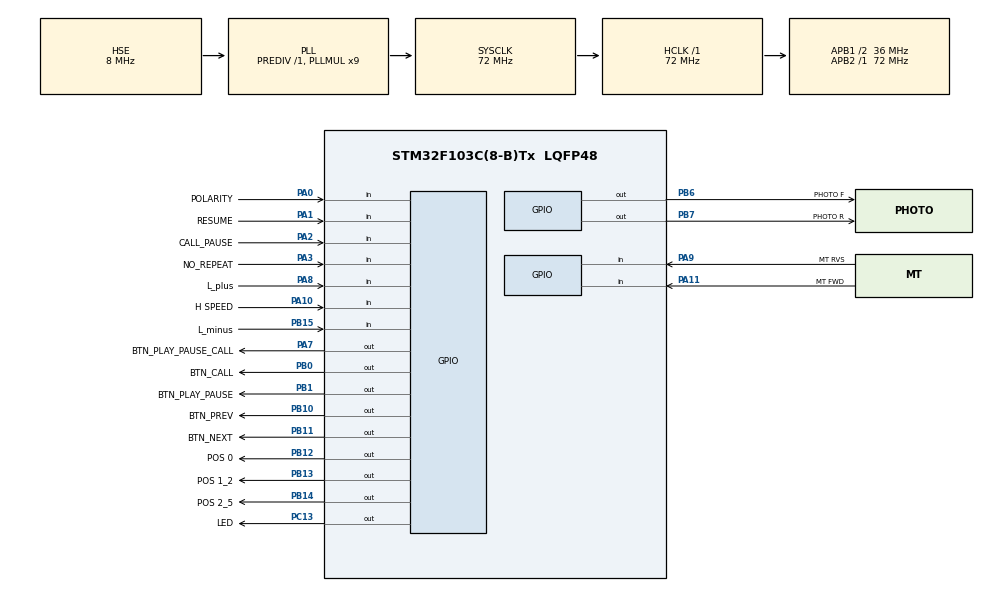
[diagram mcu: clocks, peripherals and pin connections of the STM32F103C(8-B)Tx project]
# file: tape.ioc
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Mcu.Family=STM32F1
PA2.GPIO_PuPd=GPIO_PULLUP
PB14.GPIO_Label=POS 2_5
PA3.GPIO_PuPd=GPIO_PULLUP
PA7.GPIO_ModeDefaultOutputPP=GPIO_MODE_OUTPUT_OD
PB0.GPIO_Label=BTN_CALL
PB6.GPIO_Label=PHOTO F
PB13.GPIO_Label=POS 1_2
PB11.Signal=GPIO_Output
PB13.Signal=GPIO_Output
PB15.Signal=GPIO_Input
RCC.SYSCLKSource=RCC_SYSCLKSOURCE_PLLCLK
ProjectManager.StackSize=0x10
PD1-OSC_OUT.Signal=RCC_OSC_OUT
PB10.GPIO_ModeDefaultOutputPP=GPIO_MODE_OUTPUT_OD
RCC.HCLKFreq_Value=72000000
RCC.APB2TimFreq_Value=72000000
PB6.Signal=GPIO_Output
PB13.GPIO_ModeDefaultOutputPP=GPIO_MODE_OUTPUT_OD
PB12.PinState=GPIO_PIN_SET
PA1.GPIO_PuPd=GPIO_PULLUP
RCC.AHBFreq_Value=72000000
PB12.GPIO_ModeDefaultOutputPP=GPIO_MODE_OUTPUT_OD
RCC.PLLMUL=RCC_PLL_MUL9
PB12.GPIO_Label=POS 0
PA14.Mode=Serial_Wire
PB1.GPIO_Label=BTN_PLAY_PAUSE
PA10.GPIO_Label=H SPEED
PB7.Signal=GPIO_Output
PA8.Signal=GPIO_Input
PB7.GPIO_Label=PHOTO R
Mcu.Package=LQFP48
PB1.Signal=GPIO_Output
PA2.GPIO_Label=CALL_PAUSE
PB6.GPIO_ModeDefaultOutputPP=GPIO_MODE_OUTPUT_OD
PA10.Signal=GPIO_Input
RCC.APB1TimFreq_Value=72000000
PB0.GPIO_ModeDefaultOutputPP=GPIO_MODE_OUTPUT_OD
PA3.Signal=GPIO_Input
RCC.PLLSourceVirtual=RCC_PLLSOURCE_HSE
PD1-OSC_OUT.Mode=HSE-External-Oscillator
PA9.GPIO_Label=MT RVS
PB11.GPIO_Label=BTN_NEXT
PC13-TAMPER-RTC.Signal=GPIO_Output
PA11.GPIO_Label=MT FWD
PD0-OSC_IN.Signal=RCC_OSC_IN
RCC.APB1CLKDivider=RCC_HCLK_DIV2
PA0-WKUP.GPIO_Label=POLARITY
PA0-WKUP.Signal=GPIO_Input
PA13.Signal=SYS_JTMS-SWDIO
PA8.GPIO_Label=L_plus
PB14.PinState=GPIO_PIN_SET
ProjectManager.TargetToolchain=STM32CubeIDE
PB10.GPIO_Label=BTN_PREV
PA9.Signal=GPIO_Input
RCC.USBFreq_Value=72000000
PB14.GPIO_ModeDefaultOutputPP=GPIO_MODE_OUTPUT_OD
PB11.GPIO_ModeDefaultOutputPP=GPIO_MODE_OUTPUT_OD
PA1.Signal=GPIO_Input
PD0-OSC_IN.Mode=HSE-External-Oscillator
PB10.Signal=GPIO_Output
PB14.Signal=GPIO_Output
board=custom
PC13-TAMPER-RTC.GPIO_Label=LED
RCC.APB2Freq_Value=72000000
PB13.PinState=GPIO_PIN_SET
PB15.GPIO_Label=L_minus
PB7.GPIO_ModeDefaultOutputPP=GPIO_MODE_OUTPUT_OD
PA1.GPIO_Label=RESUME
PA13.Mode=Serial_Wire
Mcu.Name=STM32F103C(8-B)Tx
PA2.Signal=GPIO_Input
RCC.SYSCLKFreq_VALUE=72000000
PA7.GPIO_Label=BTN_PLAY_PAUSE_CALL
PA11.Signal=GPIO_Input
PA14.Signal=SYS_JTCK-SWCLK
ProjectManager.HeapSize=0x10
NVIC.PriorityGroup=NVIC_PRIORITYGROUP_4
PA0-WKUP.GPIO_PuPd=GPIO_PULLUP
PB1.GPIO_ModeDefaultOutputPP=GPIO_MODE_OUTPUT_OD
RCC.APB1Freq_Value=36000000
PB0.Signal=GPIO_Output
PB12.Signal=GPIO_Output
PA3.GPIO_Label=NO_REPEAT
PA7.Signal=GPIO_Output

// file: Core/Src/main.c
/* USER CODE BEGIN Header */
/**
  ******************************************************************************
  * @file           : main.c
  * @brief          : Main program body
  ******************************************************************************
  * @attention
  *
  * <h2><center>&copy; Copyright (c) 2021 STMicroelectronics.
  * All rights reserved.</center></h2>
  *
  * This software component is licensed by ST under BSD 3-Clause license,
  * the "License"; You may not use this file except in compliance with the
  * License. You may obtain a copy of the License at:
  *                        opensource.org/licenses/BSD-3-Clause
  *
  ******************************************************************************
  */
/* USER CODE END Header */
#include "main.h"

/* USER CODE BEGIN Includes */
#include "tape.h"
/* USER CODE END Includes */

void SystemClock_Config(void);
static void MX_GPIO_Init(void);

int main(void)
{

  /* MCU Configuration--------------------------------------------------------*/

  /* Reset of all peripherals, Initializes the Flash interface and the Systick. */
  HAL_Init();

  /* Configure the system clock */
  SystemClock_Config();

  /* Initialize all configured peripherals */
  MX_GPIO_Init();
  /* USER CODE BEGIN 2 */
  HAL_Delay(10);
  initTape();														// Initialize tape settings
  /* USER CODE END 2 */

  /* Infinite loop */
  /* USER CODE BEGIN WHILE */
  while (1)
  {
	 handleTape();															// Handle Tape
    /* USER CODE END WHILE */

  }
}

void SystemClock_Config(void)
{
  RCC_OscInitTypeDef RCC_OscInitStruct = {0};
  RCC_ClkInitTypeDef RCC_ClkInitStruct = {0};

  /** Initializes the RCC Oscillators according to the specified parameters
  * in the RCC_OscInitTypeDef structure.
  */
  RCC_OscInitStruct.OscillatorType = RCC_OSCILLATORTYPE_HSE;
  RCC_OscInitStruct.HSEState = RCC_HSE_ON;
  RCC_OscInitStruct.HSEPredivValue = RCC_HSE_PREDIV_DIV1;
  RCC_OscInitStruct.HSIState = RCC_HSI_ON;
  RCC_OscInitStruct.PLL.PLLState = RCC_PLL_ON;
  RCC_OscInitStruct.PLL.PLLSource = RCC_PLLSOURCE_HSE;
  RCC_OscInitStruct.PLL.PLLMUL = RCC_PLL_MUL9;
  if (HAL_RCC_OscConfig(&RCC_OscInitStruct) != HAL_OK)
  {
    Error_Handler();
  }
  /** Initializes the CPU, AHB and APB buses clocks
  */
  RCC_ClkInitStruct.ClockType = RCC_CLOCKTYPE_HCLK|RCC_CLOCKTYPE_SYSCLK
                              |RCC_CLOCKTYPE_PCLK1|RCC_CLOCKTYPE_PCLK2;
  RCC_ClkInitStruct.SYSCLKSource = RCC_SYSCLKSOURCE_PLLCLK;
  RCC_ClkInitStruct.AHBCLKDivider = RCC_SYSCLK_DIV1;
  RCC_ClkInitStruct.APB1CLKDivider = RCC_HCLK_DIV2;
  RCC_ClkInitStruct.APB2CLKDivider = RCC_HCLK_DIV1;

  if (HAL_RCC_ClockConfig(&RCC_ClkInitStruct, FLASH_LATENCY_2) != HAL_OK)
  {
    Error_Handler();
  }
}

static void MX_GPIO_Init(void)
{
  GPIO_InitTypeDef GPIO_InitStruct = {0};

  /* GPIO Ports Clock Enable */
  __HAL_RCC_GPIOC_CLK_ENABLE();
  __HAL_RCC_GPIOD_CLK_ENABLE();
  __HAL_RCC_GPIOA_CLK_ENABLE();
  __HAL_RCC_GPIOB_CLK_ENABLE();

  /*Configure GPIO pin Output Level */
  HAL_GPIO_WritePin(LED_GPIO_Port, LED_Pin, GPIO_PIN_RESET);

  /*Configure GPIO pin Output Level */
  HAL_GPIO_WritePin(BTN_PLAY_PAUSE_CALL_GPIO_Port, BTN_PLAY_PAUSE_CALL_Pin, GPIO_PIN_RESET);

  /*Configure GPIO pin Output Level */
  HAL_GPIO_WritePin(GPIOB, BTN_CALL_Pin|BTN_PLAY_PAUSE_Pin|BTN_PREV_Pin|BTN_NEXT_Pin
                          |PHOTO_F_Pin|PHOTO_R_Pin, GPIO_PIN_RESET);

  /*Configure GPIO pin Output Level */
  HAL_GPIO_WritePin(GPIOB, POS_0_Pin|POS_1_2_Pin|POS_2_5_Pin, GPIO_PIN_SET);

  /*Configure GPIO pin : LED_Pin */
  GPIO_InitStruct.Pin = LED_Pin;
  GPIO_InitStruct.Mode = GPIO_MODE_OUTPUT_PP;
  GPIO_InitStruct.Pull = GPIO_NOPULL;
  GPIO_InitStruct.Speed = GPIO_SPEED_FREQ_LOW;
  HAL_GPIO_Init(LED_GPIO_Port, &GPIO_InitStruct);

  /*Configure GPIO pins : POLARITY_Pin RESUME_Pin CALL_PAUSE_Pin */
  GPIO_InitStruct.Pin = POLARITY_Pin|RESUME_Pin|CALL_PAUSE_Pin;
  GPIO_InitStruct.Mode = GPIO_MODE_INPUT;
  GPIO_InitStruct.Pull = GPIO_PULLUP;
  HAL_GPIO_Init(GPIOA, &GPIO_InitStruct);

  /*Configure GPIO pin : BTN_PLAY_PAUSE_CALL_Pin */
  GPIO_InitStruct.Pin = BTN_PLAY_PAUSE_CALL_Pin;
  GPIO_InitStruct.Mode = GPIO_MODE_OUTPUT_OD;
  GPIO_InitStruct.Pull = GPIO_NOPULL;
  GPIO_InitStruct.Speed = GPIO_SPEED_FREQ_LOW;
  HAL_GPIO_Init(BTN_PLAY_PAUSE_CALL_GPIO_Port, &GPIO_InitStruct);

  /*Configure GPIO pins : BTN_CALL_Pin BTN_PLAY_PAUSE_Pin BTN_PREV_Pin BTN_NEXT_Pin
                           POS_0_Pin POS_1_2_Pin POS_2_5_Pin PHOTO_F_Pin
                           PHOTO_R_Pin */
  GPIO_InitStruct.Pin = BTN_CALL_Pin|BTN_PLAY_PAUSE_Pin|BTN_PREV_Pin|BTN_NEXT_Pin
                          |POS_0_Pin|POS_1_2_Pin|POS_2_5_Pin|PHOTO_F_Pin
                          |PHOTO_R_Pin;
  GPIO_InitStruct.Mode = GPIO_MODE_OUTPUT_OD;
  GPIO_InitStruct.Pull = GPIO_NOPULL;
  GPIO_InitStruct.Speed = GPIO_SPEED_FREQ_LOW;
  HAL_GPIO_Init(GPIOB, &GPIO_InitStruct);

  /*Configure GPIO pin : L_minus_Pin */
  GPIO_InitStruct.Pin = L_minus_Pin;
  GPIO_InitStruct.Mode = GPIO_MODE_INPUT;
  GPIO_InitStruct.Pull = GPIO_NOPULL;
  HAL_GPIO_Init(L_minus_GPIO_Port, &GPIO_InitStruct);

  /*Configure GPIO pins : L_plus_Pin MT_RVS_Pin H_SPEED_Pin MT_FWD_Pin */
  GPIO_InitStruct.Pin = L_plus_Pin|MT_RVS_Pin|H_SPEED_Pin|MT_FWD_Pin;
  GPIO_InitStruct.Mode = GPIO_MODE_INPUT;
  GPIO_InitStruct.Pull = GPIO_NOPULL;
  HAL_GPIO_Init(GPIOA, &GPIO_InitStruct);

}

void Error_Handler(void)
{
  __disable_irq();
  while (1)
  {
  }
}

/************************ (C) COPYRIGHT STMicroelectronics *****END OF FILE****/
